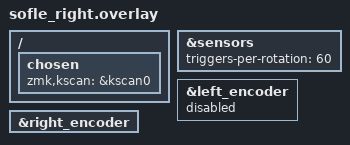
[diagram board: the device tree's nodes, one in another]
/ {
    chosen {
        zmk,kscan = &kscan0;
    };
};

/* Override the sensors node to change triggers-per-rotation */
&sensors {
    triggers-per-rotation = <60>; /* Change from default 20 to 60 */
};

/* Ensure left encoder is disabled on right half */
&left_encoder {
    status = "disabled";
};

/* Ensure right encoder is enabled on right half */
&right_encoder {
    status = "okay";
};
